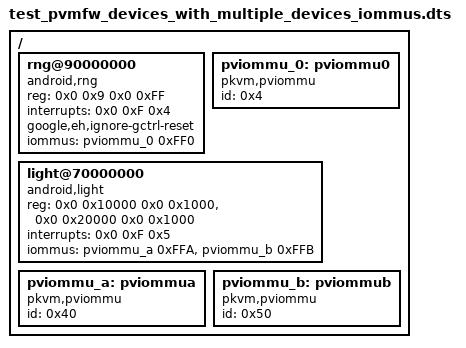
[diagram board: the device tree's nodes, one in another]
/dts-v1/;

/include/ "test_crosvm_dt_base.dtsi"
/ {
    rng@90000000 {
        compatible = "android,rng";
        reg = <0x0 0x9 0x0 0xFF>;
        interrupts = <0x0 0xF 0x4>;
        google,eh,ignore-gctrl-reset;
        status = "okay";
        iommus = <&pviommu_0 0xFF0>;
    };

    pviommu_0: pviommu0 {
        compatible = "pkvm,pviommu";
        id = <0x4>;
        #iommu-cells = <1>;
    };

    light@70000000 {
        compatible = "android,light";
        reg = <0x0 0x10000 0x0 0x1000>, <0x0 0x20000 0x0 0x1000>;
        interrupts = <0x0 0xF 0x5>;
        iommus = <&pviommu_a 0xFFA>, <&pviommu_b 0xFFB>;
    };

    pviommu_a: pviommua {
        compatible = "pkvm,pviommu";
        id = <0x40>;
        #iommu-cells = <1>;
    };

    pviommu_b: pviommub {
        compatible = "pkvm,pviommu";
        id = <0x50>;
        #iommu-cells = <1>;
    };
};
